# ATtiny861 device description
Architecture: AVR8; Family: tinyAVR
Registers are 8-bit, access not given, no defined reset value unless marked. A register's access mark holds for its fields unless they carry their own. Offsets are from the block's base; [hi:lo] are bit positions; {n}, {i} and the like mark numbered series.

## LOCKBIT — Lockbits
Instances: LOCKBIT 0 in lockbits
0x00 LOCKBIT reset 0xFF
  [1:0] LB — Memory Lock
    0=PROG_VER_DISABLED (Further programming and verification disabled); 2=PROG_DISABLED (Further programming disabled); 3=NO_LOCK (No memory lock features enabled)

## PORTA — I/O Port
Instances: PORTA 0x00
0x39 PINA — Port A Input Pins
0x3A DDRA — Port A Data Direction Register
0x3B PORTA — Port A Data Register

## PORTB — I/O Port
Instances: PORTB 0x00
0x36 PINB — Port B Input Pins
0x37 DDRB — Port B Data Direction Register
0x38 PORTB — Port B Data Register

## ADC — Analog-to-Digital Converter
Instances: ADC 0x00
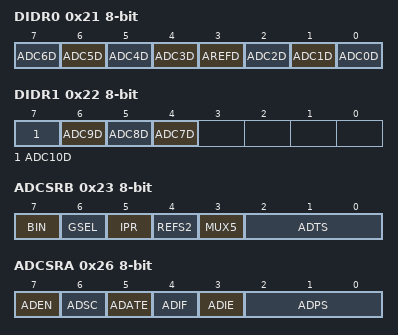
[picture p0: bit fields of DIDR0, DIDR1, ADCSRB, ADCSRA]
0x21 DIDR0 — Digital Input Disable Register 0
  [n+1] ADC{n}D (n=3..6) — ADC{n} Digital input Disable
  [3] AREFD — AREF Digital Input Disable
  [2] ADC2D — ADC2 Digital input Disable
  [1] ADC1D — ADC1 Digital input Disable
  [0] ADC0D — ADC0 Digital input Disable
0x22 DIDR1 — Digital Input Disable Register 1
  [n-3] ADC{n}D (n=7..10) — ADC{n} Digital input Disable
0x23 ADCSRB — ADC Control and Status Register B
  [7] BIN — Bipolar Input Mode
  [6] GSEL — Gain Select
  [5] IPR — Input Polarity Mode
  [4] REFS2 — Reference Selection Bit
  [3] MUX5 — Analog Channel and Gain Selection Bit 5
  [2:0] ADTS — ADC Auto Trigger Sources
    0=Free Running mode; 1=Analog Comparator; 2=External Interrupt Request 0; 3=Timer/Counter0 Compare Match A; 4=Timer/Counter0 Overflow; 5=Timer/Counter1 Compare Match B; 6=Timer/Counter1 Overflow; 7=Watchdog Interrupt Request
0x24 ADC 16-bit — ADC Data Register Bytes
0x26 ADCSRA — The ADC Control and Status register
  [7] ADEN — ADC Enable
  [6] ADSC — ADC Start Conversion
  [5] ADATE — ADC Auto Trigger Enable
  [4] ADIF — ADC Interrupt Flag
  [3] ADIE — ADC Interrupt Enable
  [2:0] ADPS — ADC Prescaler Select Bits
    0=2; 1=2; 2=4; 3=8; 4=16; 5=32; 6=64; 7=128
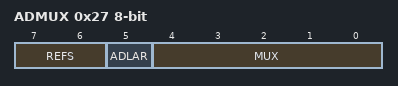
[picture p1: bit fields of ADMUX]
0x27 ADMUX — The ADC multiplexer Selection Register
  [7:6] REFS — Reference Selection Bits
  [5] ADLAR — Left Adjust Result
  [4:0] MUX — Analog Channel and Gain Selection Bits

## AC — Analog Comparator
Instances: AC 0x00
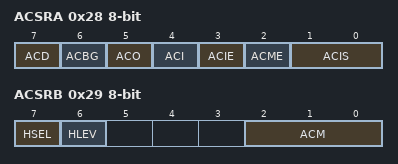
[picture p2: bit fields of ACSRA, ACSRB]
0x28 ACSRA — Analog Comparator Control And Status Register A
  [7] ACD — Analog Comparator Disable
  [6] ACBG — Analog Comparator Bandgap Select
  [5] ACO — Analog Compare Output
  [4] ACI — Analog Comparator Interrupt Flag
  [3] ACIE — Analog Comparator Interrupt Enable
  [2] ACME — Analog Comparator Multiplexer Enable
  [1:0] ACIS — Analog Comparator Interrupt Mode Select bits
    0=Interrupt on Toggle; 2=Interrupt on Falling Edge; 3=Interrupt on Rising Edge
0x29 ACSRB — Analog Comparator Control And Status Register B
  [7] HSEL — Hysteresis Select
  [6] HLEV — Hysteresis Level
  [2:0] ACM — Analog Comparator Multiplexer

## USI — Universal Serial Interface
Instances: USI 0x00
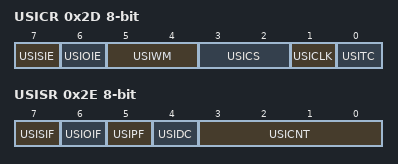
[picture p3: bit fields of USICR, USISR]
0x2D USICR — USI Control Register
  [7] USISIE — Start Condition Interrupt Enable
  [6] USIOIE — Counter Overflow Interrupt Enable
  [5:4] USIWM — USI Wire Mode Bits
    0=Normal Operation; 1=Three-Wire Mode; 2=Two-Wire Mode; 3=Two-Wire Mode Held Low
  [3:2] USICS — USI Clock Source Select Bits
  [1] USICLK — Clock Strobe
  [0] USITC — Toggle Clock Port Pin
0x2E USISR — USI Status Register
  [7] USISIF — Start Condition Interrupt Flag
  [6] USIOIF — Counter Overflow Interrupt Flag
  [5] USIPF — Stop Condition Flag
  [4] USIDC — Data Output Collision
  [3:0] USICNT — USI Counter Value Bits
0x2F USIDR — USI Data Register
0x30 USIBR — USI Buffer Register
0x31 USIPP bits used 0 — USI Pin Position

## EEPROM
Instances: EEPROM 0x00
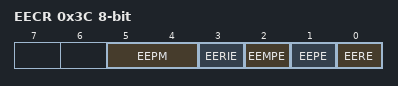
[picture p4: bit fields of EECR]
0x3C EECR — EEPROM Control Register
  [5:4] EEPM — EEPROM Programming Mode Bits
    0=Erase and Write in one operation; 1=Erase Only; 2=Write Only
  [3] EERIE — EEPROM Ready Interrupt Enable
  [2] EEMPE — EEPROM Master Write Enable
  [1] EEPE — EEPROM Write Enable
  [0] EERE — EEPROM Read Enable
0x3D EEDR — EEPROM Data Register
0x3E EEAR 16-bit bits used 8:0 — EEPROM Address Register Bytes
